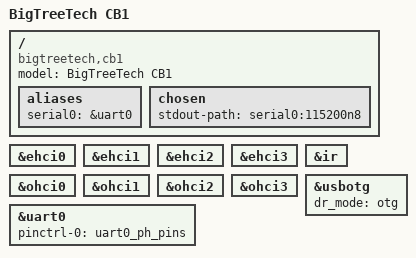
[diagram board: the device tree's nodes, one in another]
// SPDX-License-Identifier: (GPL-2.0+ OR MIT)
/*
 * Copyright (C) 2023 Martin Botka <martin@biqu3d.com>.
 */

/dts-v1/;

#include "sun50i-h616-bigtreetech-cb1.dtsi"

/ {
	model = "BigTreeTech CB1";
	compatible = "bigtreetech,cb1", "allwinner,sun50i-h616";

	aliases {
		serial0 = &uart0;
	};

	chosen {
		stdout-path = "serial0:115200n8";
	};
};

&ehci0 {
	status = "okay";
};

&ehci1 {
	status = "okay";
};

&ehci2 {
	status = "okay";
};

&ehci3 {
	status = "okay";
};

&ir {
	status = "okay";
};

&ohci0 {
	status = "okay";
};

&ohci1 {
	status = "okay";
};

&ohci2 {
	status = "okay";
};

&ohci3 {
	status = "okay";
};

&uart0 {
	pinctrl-names = "default";
	pinctrl-0 = <&uart0_ph_pins>;
	status = "okay";
};

&usbotg {
	/*
	 * PHY0 pins are connected to a USB-C socket, but a role switch
	 * is not implemented: both CC pins are pulled to GND.
	 * The VBUS pins power the device, so a fixed peripheral mode
	 * is the best choice.
	 * The board can be powered via GPIOs, in this case port0 *can*
	 * act as a host (with a cable/adapter ignoring CC), as VBUS is
	 * then provided by the GPIOs. Any user of this setup would
	 * need to adjust the DT accordingly: dr_mode set to "host",
	 * enabling OHCI0 and EHCI0.
	 */
	dr_mode = "otg";
	status = "okay";
};
